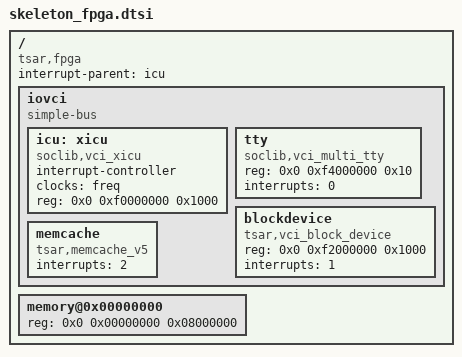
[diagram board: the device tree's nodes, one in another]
/*
 * Skeleton DTS file for TSAR on FPGA
 */

/include/ "skeleton.dtsi"

/ {
	compatible = "tsar,fpga";
	interrupt-parent = <&icu>;

	iovci {
		compatible = "simple-bus";
		#address-cells = <2>;
		#size-cells = <1>;
		ranges; // identity mapping between root addressing and vci network

		icu: xicu {
			compatible = "soclib,vci_xicu", "soclib,vci_xicu_timer";
			interrupt-controller;
			#interrupt-cells = <1>;
			clocks = <&freq>;
			reg = <0x0 0xf0000000 0x1000>;
		};

		tty: tty {
			compatible = "soclib,vci_multi_tty";
			reg = <0x0 0xf4000000 0x10>;
			interrupts = <0>;
		};

		blockdevice {
			compatible = "tsar,vci_block_device";
			reg = <0x0 0xf2000000 0x1000>;
			interrupts = <1>;
		};

		/*
		framebuffer {
			compatible = "tsar,vci_framebuffer", "simple-framebuffer";
			reg = <0x0 0xf3000000 (640 * 680 * 2)>;
			width = <640>;
			height = <480>;
			stride = <(640 * 2)>;
			format = "r5g6b5";
		};
		*/

		memcache {
			compatible = "tsar,memcache_v5";
			interrupts = <2>;
		};
	};

	memory@0x00000000 {
		device_type = "memory";
		reg = <0x0 0x00000000 0x08000000>;
	};
};
